VERSION "1.0"

NS_ :

BS_:

BU_: PCM1 FOO

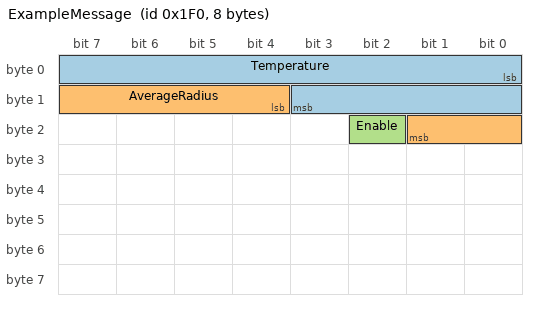
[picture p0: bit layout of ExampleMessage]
BO_ 496 ExampleMessage: 8 PCM1
 SG_ Temperature : 0|12@1- (0.01,250) [229.52|270.47] "degK"  PCM1,FOO
 SG_ AverageRadius : 12|6@1+ (0.1,0) [0|5] "m" Vector__XXX
 SG_ Enable : 18|1@1+ (1,0) [0|0] "-" Vector__XXX

CM_ BO_ 496 "Example message used as template in MotoHawk models.";

VAL_ 496 Enable 0 "Disabled" 1 "Enabled" ;
